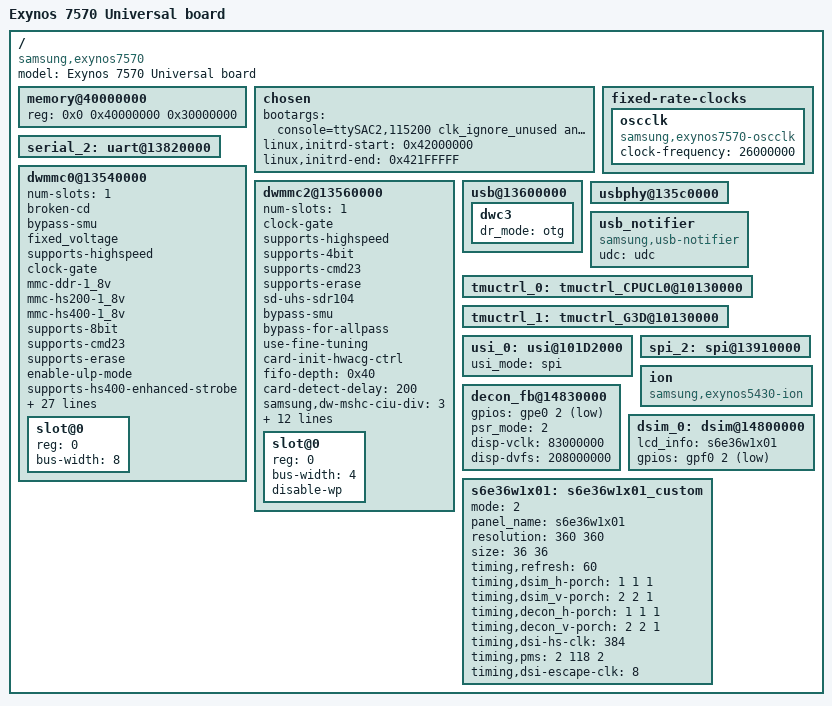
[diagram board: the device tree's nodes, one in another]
/*
 * SAMSUNG UNIVERSAL7270 board device tree source
 *
 * Copyright (c) 2013 Samsung Electronics Co., Ltd.
 *		http://www.samsung.com
 *
 * This program is free software; you can redistribute it and/or modify
 * it under the terms of the GNU General Public License version 2 as
 * published by the Free Software Foundation.
*/

/dts-v1/;
#include "exynos7270.dtsi"

/ {
	model = "Exynos 7570 Universal board";
	compatible = "samsung,exynos7570", "samsung,exynos4210";

	memory@40000000 {
		device_type = "memory";
		reg = <0x0 0x40000000 0x30000000>;
	};

	chosen {
		bootargs = "console=ttySAC2,115200 clk_ignore_unused androidboot.hardware=samsungexynos7570 androidboot.selinux=disabled firmware_class.path=/vendor/firmware ess_setup=0x46000000";
		linux,initrd-start = <0x42000000>;
		linux,initrd-end = <0x421FFFFF>;
	};

	fixed-rate-clocks {
		oscclk {
			compatible = "samsung,exynos7570-oscclk";
			clock-frequency = <26000000>;
		};
	};

	serial_2: uart@13820000 {
		status = "okay";
	};

	dwmmc0@13540000 {
		status = "okay";
		num-slots = <1>;
		broken-cd;
		bypass-smu;
		fixed_voltage;
		supports-highspeed;
		clock-gate;
		mmc-ddr-1_8v;
		mmc-hs200-1_8v;
		mmc-hs400-1_8v;
		supports-8bit;
		supports-cmd23;
		supports-erase;
		enable-ulp-mode;
		supports-hs400-enhanced-strobe;
		use-fine-tuning;
		bypass-for-allpass;
		card-init-hwacg-ctrl;
		fifo-depth = <0x40>;
		non-removable;
		card-detect-delay = <200>;
		clock-frequency = <700000000>;
		samsung,dw-mshc-ciu-div = <3>;
		samsung,dw-mshc-txdt-crc-timer-fastlimit = <0x34>;
		samsung,dw-mshc-txdt-crc-timer-initval = <0x38>;
		samsung,dw-mshc-ddr200-delay-line = <0x50>;
		samsung,dw-mshc-sdr-timing = <3 0 4 0>;
		samsung,dw-mshc-ddr-timing = <3 0 4 2>;
		samsung,dw-mshc-hs200-timing = <3 0 3 0>;
		samsung,dw-mshc-ddr200-timing = <1 0 4 0>;
		samsung,dw-mshc-ddr200-ulp-timing = <3 0 4 0>;

		num-ref-clks = <10>;
		ciu_clkin = <25 43 43 87 175 43 43 175 175 175>;

		/* Swapping clock drive strength */
		clk-drive-number = <6>;
		pinctrl-names = "default",
			"fast-slew-rate-1x",
			"fast-slew-rate-2x",
			"fast-slew-rate-3x",
			"fast-slew-rate-4x",
			"fast-slew-rate-5x",
			"fast-slew-rate-6x";
		pinctrl-0 = <&sd0_clk &sd0_cmd &sd0_rdqs &sd0_bus1 &sd0_bus4 &sd0_bus8>;
		pinctrl-1 = <&sd0_clk_fast_slew_rate_1x>;
		pinctrl-2 = <&sd0_clk_fast_slew_rate_2x>;
		pinctrl-3 = <&sd0_clk_fast_slew_rate_3x>;
		pinctrl-4 = <&sd0_clk_fast_slew_rate_4x>;
		pinctrl-5 = <&sd0_clk_fast_slew_rate_5x>;
		pinctrl-6 = <&sd0_clk_fast_slew_rate_6x>;
		slot@0 {
			reg = <0>;
			bus-width = <8>;
		};
	};

	dwmmc2@13560000 {
		status = "okay";
		num-slots = <1>;
		clock-gate;
		supports-highspeed;
		supports-4bit;
		supports-cmd23;
		supports-erase;
		sd-uhs-sdr104;
		bypass-smu;
		bypass-for-allpass;
		use-fine-tuning;
		card-init-hwacg-ctrl;
		fifo-depth = <0x40>;
		card-detect-delay = <200>;
		samsung,dw-mshc-ciu-div = <3>;
		samsung,dw-mshc-sdr-timing = <3 0 2 0>;
		samsung,dw-mshc-ddr-timing = <3 0 2 1>;

		num-ref-clks = <6>;
		ciu_clkin = <25 43 43 87 175 43>;

		clk-drive-number = <4>;
		pinctrl-names = "default",
			"fast-slew-rate-1x",
			"fast-slew-rate-2x",
			"fast-slew-rate-3x",
			"fast-slew-rate-4x";
		pinctrl-0 = <&sd2_clk &sd2_cmd &sd2_bus1 &sd2_bus4 &dwmmc2_cd_ext_irq>;
		pinctrl-1 = <&sd2_clk_fast_slew_rate_1x>;
		pinctrl-2 = <&sd2_clk_fast_slew_rate_2x>;
		pinctrl-3 = <&sd2_clk_fast_slew_rate_3x>;
		pinctrl-4 = <&sd2_clk_fast_slew_rate_4x>;

		card-detect = <&gpa0 1 0xf>;
		slot@0 {
			reg = <0>;
			bus-width = <4>;
			disable-wp;
		};
	};

	usb@13600000 {
		status = "okay";

		dwc3 {
			dr_mode = "otg";
		};
	};

	usbphy@135c0000 {
		status = "okay";
	};

	usb_notifier {
		compatible = "samsung,usb-notifier";
		udc = <&udc>;
	};

	tmuctrl_0: tmuctrl_CPUCL0@10130000 {
	};

	tmuctrl_1: tmuctrl_G3D@10130000 {
	};

	usi_0: usi@101D2000 {
		usi_mode = "spi";
		status = "okay";
	};

	spi_2: spi@13910000 {
		status = "okay";
	};

	ion {
		compatible = "samsung,exynos5430-ion";
	};

	decon_fb@14830000 {
		gpios = <&gpe0 2 0xf>;
		psr_mode = <2>; /* 0: video mode, 1: DP command mode, 2: MIPI command mode */
		/* vclk = 100Mhz */
		disp-vclk = <83000000>;
		/* aclk = 208Mhz */
		disp-dvfs = <208000000>;
		status = "okay";
	};

	dsim_0: dsim@14800000 {
		lcd_info = <&s6e36w1x01>;
		/*lcd reset */
		gpios = <&gpf0 2 0x1>;
		status = "okay";
	};

	s6e36w1x01: s6e36w1x01_custom {
		mode = <2>; /* 0: video mode, 1: DP command mode, 2: MIPI command mode */
		/* custom(360 x 360) */
		panel_name = "s6e36w1x01";
		resolution = <360 360>;
		size = <36 36>;
		timing,refresh = <60>;
		/* dsim H porch : hbp, hfp, hsa */
		timing,dsim_h-porch = <1 1 1>;
		/* dsim V porch : VBP, VFP, VSA */
		timing,dsim_v-porch = <2 2 1>;
		/* decon H porch : hbp, hfp, hsa */
		timing,decon_h-porch = <1 1 1>;
		/* decon V porch : VBP, VFP, VSA */
		timing,decon_v-porch = <2 2 1>;
		timing,dsi-hs-clk = <384>; /* panel max speed : 384Mbps */
		timing,pms = <2 118 2>;
		timing,dsi-escape-clk = <8>;
	};

};
